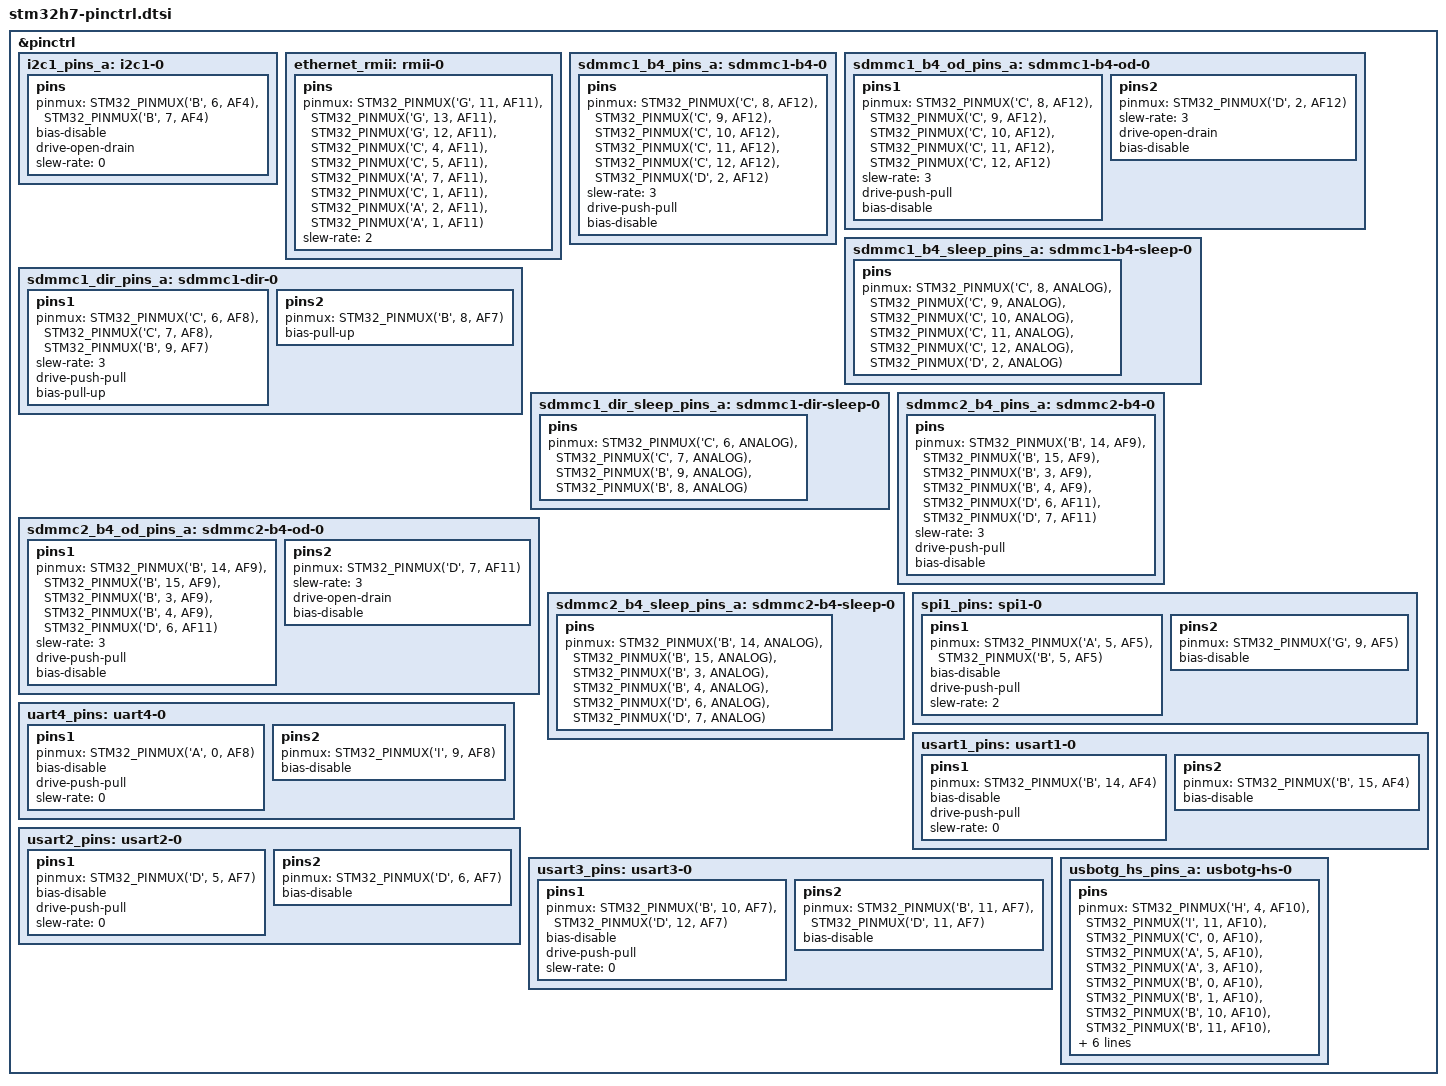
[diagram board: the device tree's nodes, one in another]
#include <dt-bindings/pinctrl/stm32-pinfunc.h>
&pinctrl {
	i2c1_pins_a: i2c1-0 {
		pins {
			pinmux = <STM32_PINMUX('B', 6, AF4)>,  
				 <STM32_PINMUX('B', 7, AF4)>;  
			bias-disable;
			drive-open-drain;
			slew-rate = <0>;
		};
	};
	ethernet_rmii: rmii-0 {
		pins {
			pinmux = <STM32_PINMUX('G', 11, AF11)>,
				 <STM32_PINMUX('G', 13, AF11)>,
				 <STM32_PINMUX('G', 12, AF11)>,
				 <STM32_PINMUX('C', 4, AF11)>,
				 <STM32_PINMUX('C', 5, AF11)>,
				 <STM32_PINMUX('A', 7, AF11)>,
				 <STM32_PINMUX('C', 1, AF11)>,
				 <STM32_PINMUX('A', 2, AF11)>,
				 <STM32_PINMUX('A', 1, AF11)>;
			slew-rate = <2>;
		};
	};
	sdmmc1_b4_pins_a: sdmmc1-b4-0 {
		pins {
			pinmux = <STM32_PINMUX('C', 8, AF12)>,  
				 <STM32_PINMUX('C', 9, AF12)>,  
				 <STM32_PINMUX('C', 10, AF12)>,  
				 <STM32_PINMUX('C', 11, AF12)>,  
				 <STM32_PINMUX('C', 12, AF12)>,  
				 <STM32_PINMUX('D', 2, AF12)>;  
			slew-rate = <3>;
			drive-push-pull;
			bias-disable;
		};
	};
	sdmmc1_b4_od_pins_a: sdmmc1-b4-od-0 {
		pins1 {
			pinmux = <STM32_PINMUX('C', 8, AF12)>,  
				 <STM32_PINMUX('C', 9, AF12)>,  
				 <STM32_PINMUX('C', 10, AF12)>,  
				 <STM32_PINMUX('C', 11, AF12)>,  
				 <STM32_PINMUX('C', 12, AF12)>;  
			slew-rate = <3>;
			drive-push-pull;
			bias-disable;
		};
		pins2 {
			pinmux = <STM32_PINMUX('D', 2, AF12)>;  
			slew-rate = <3>;
			drive-open-drain;
			bias-disable;
		};
	};
	sdmmc1_b4_sleep_pins_a: sdmmc1-b4-sleep-0 {
		pins {
			pinmux = <STM32_PINMUX('C', 8, ANALOG)>,  
				 <STM32_PINMUX('C', 9, ANALOG)>,  
				 <STM32_PINMUX('C', 10, ANALOG)>,  
				 <STM32_PINMUX('C', 11, ANALOG)>,  
				 <STM32_PINMUX('C', 12, ANALOG)>,  
				 <STM32_PINMUX('D', 2, ANALOG)>;  
		};
	};
	sdmmc1_dir_pins_a: sdmmc1-dir-0 {
		pins1 {
			pinmux = <STM32_PINMUX('C', 6, AF8)>,  
				 <STM32_PINMUX('C', 7, AF8)>,  
				 <STM32_PINMUX('B', 9, AF7)>;  
			slew-rate = <3>;
			drive-push-pull;
			bias-pull-up;
		};
		pins2 {
			pinmux = <STM32_PINMUX('B', 8, AF7)>;  
			bias-pull-up;
		};
	};
	sdmmc1_dir_sleep_pins_a: sdmmc1-dir-sleep-0 {
		pins {
			pinmux = <STM32_PINMUX('C', 6, ANALOG)>,  
				 <STM32_PINMUX('C', 7, ANALOG)>,  
				 <STM32_PINMUX('B', 9, ANALOG)>,  
				 <STM32_PINMUX('B', 8, ANALOG)>;  
		};
	};
	sdmmc2_b4_pins_a: sdmmc2-b4-0 {
		pins {
			pinmux = <STM32_PINMUX('B', 14, AF9)>,  
				 <STM32_PINMUX('B', 15, AF9)>,  
				 <STM32_PINMUX('B', 3, AF9)>,  
				 <STM32_PINMUX('B', 4, AF9)>,  
				 <STM32_PINMUX('D', 6, AF11)>,  
				 <STM32_PINMUX('D', 7, AF11)>;  
			slew-rate = <3>;
			drive-push-pull;
			bias-disable;
		};
	};
	sdmmc2_b4_od_pins_a: sdmmc2-b4-od-0 {
		pins1 {
			pinmux = <STM32_PINMUX('B', 14, AF9)>,  
				 <STM32_PINMUX('B', 15, AF9)>,  
				 <STM32_PINMUX('B', 3, AF9)>,  
				 <STM32_PINMUX('B', 4, AF9)>,  
				 <STM32_PINMUX('D', 6, AF11)>;  
			slew-rate = <3>;
			drive-push-pull;
			bias-disable;
		};
		pins2 {
			pinmux = <STM32_PINMUX('D', 7, AF11)>;  
			slew-rate = <3>;
			drive-open-drain;
			bias-disable;
		};
	};
	sdmmc2_b4_sleep_pins_a: sdmmc2-b4-sleep-0 {
		pins {
			pinmux = <STM32_PINMUX('B', 14, ANALOG)>,  
				 <STM32_PINMUX('B', 15, ANALOG)>,  
				 <STM32_PINMUX('B', 3, ANALOG)>,  
				 <STM32_PINMUX('B', 4, ANALOG)>,  
				 <STM32_PINMUX('D', 6, ANALOG)>,  
				 <STM32_PINMUX('D', 7, ANALOG)>;  
		};
	};
	spi1_pins: spi1-0 {
		pins1 {
			pinmux = <STM32_PINMUX('A', 5, AF5)>,
				 <STM32_PINMUX('B', 5, AF5)>;
			bias-disable;
			drive-push-pull;
			slew-rate = <2>;
		};
		pins2 {
			pinmux = <STM32_PINMUX('G', 9, AF5)>;
			bias-disable;
		};
	};
	uart4_pins: uart4-0 {
		pins1 {
			pinmux = <STM32_PINMUX('A', 0, AF8)>;  
			bias-disable;
			drive-push-pull;
			slew-rate = <0>;
		};
		pins2 {
			pinmux = <STM32_PINMUX('I', 9, AF8)>;  
			bias-disable;
		};
	};
	usart1_pins: usart1-0 {
		pins1 {
			pinmux = <STM32_PINMUX('B', 14, AF4)>;  
			bias-disable;
			drive-push-pull;
			slew-rate = <0>;
		};
		pins2 {
			pinmux = <STM32_PINMUX('B', 15, AF4)>;  
			bias-disable;
		};
	};
	usart2_pins: usart2-0 {
		pins1 {
			pinmux = <STM32_PINMUX('D', 5, AF7)>;  
			bias-disable;
			drive-push-pull;
			slew-rate = <0>;
		};
		pins2 {
			pinmux = <STM32_PINMUX('D', 6, AF7)>;  
			bias-disable;
		};
	};
	usart3_pins: usart3-0 {
		pins1 {
			pinmux = <STM32_PINMUX('B', 10, AF7)>,  
				 <STM32_PINMUX('D', 12, AF7)>;  
			bias-disable;
			drive-push-pull;
			slew-rate = <0>;
		};
		pins2 {
			pinmux = <STM32_PINMUX('B', 11, AF7)>,  
				 <STM32_PINMUX('D', 11, AF7)>;  
			bias-disable;
		};
	};
	usbotg_hs_pins_a: usbotg-hs-0 {
		pins {
			pinmux = <STM32_PINMUX('H', 4, AF10)>,	 
					 <STM32_PINMUX('I', 11, AF10)>,  
					 <STM32_PINMUX('C', 0, AF10)>,	 
					 <STM32_PINMUX('A', 5, AF10)>,	 
					 <STM32_PINMUX('A', 3, AF10)>,	 
					 <STM32_PINMUX('B', 0, AF10)>,	 
					 <STM32_PINMUX('B', 1, AF10)>,	 
					 <STM32_PINMUX('B', 10, AF10)>,  
					 <STM32_PINMUX('B', 11, AF10)>,  
					 <STM32_PINMUX('B', 12, AF10)>,  
					 <STM32_PINMUX('B', 13, AF10)>,  
					 <STM32_PINMUX('B', 5, AF10)>;	 
			bias-disable;
			drive-push-pull;
			slew-rate = <2>;
		};
	};
};
